# V32F20x_CM0 register map
File version: 1.0.1
CPU: CM0 r0p0, little endian, no MPU, no FPU, 2 interrupt priority bits
Registers are 32-bit, read-write, reset 0x0 unless marked. A register's access mark holds for its fields unless they carry their own. Offsets are from the block's base; [hi:lo] are bit positions; {n}, {i} and the like mark numbered series.

## BPWMMUX1 — BPWMMUX1 Peripheral Interface
Base 0x410501F0
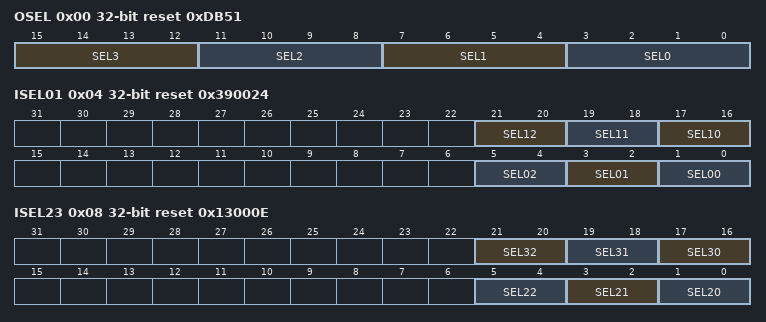
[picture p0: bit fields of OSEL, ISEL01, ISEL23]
0x00 OSEL reset 0xDB51 — BPWM output select register.
  [15:12] SEL3 — External output pin selected register for PWM3
  [11:8] SEL2 — External output pin selected register for PWM2
  [7:4] SEL1 — External output pin selected register for PWM1
  [3:0] SEL0 — External output pin selected register for PWM0.
0x04 ISEL01 reset 0x390024 — BPWM0 BPWM1 input select register.
  [21:20] SEL12 — The external input control of PWM1 channel 2 IN2
  [19:18] SEL11 — The external input control of PWM1 channel 1 IN1
  [17:16] SEL10 — The external output control of PWM1 channel 0 IN0
  [5:4] SEL02 — The external input control of PWM0 channel 2 IN2
  [3:2] SEL01 — The external input control of PWM0 channel 1 IN1
  [1:0] SEL00 — The external input control of PWM0 channel 0 IN0
0x08 ISEL23 reset 0x13000E — BPWM2 BPWM3 input select register.
  [21:20] SEL32 — The external input control of PWM3 channel 2 IN2
  [19:18] SEL31 — The external input control of PWM3 channel 1 IN1
  [17:16] SEL30 — The external input control of PWM3 channle 0 IN0
  [5:4] SEL22 — The external input control of PWM2 channel 2 IN2
  [3:2] SEL21 — The external input control of PWM2 channel 1 IN1
  [1:0] SEL20 — The external input control of PWM2 channel 0 IN0

## BDMA — BDMA Peripheral Interface
Base 0x41080800
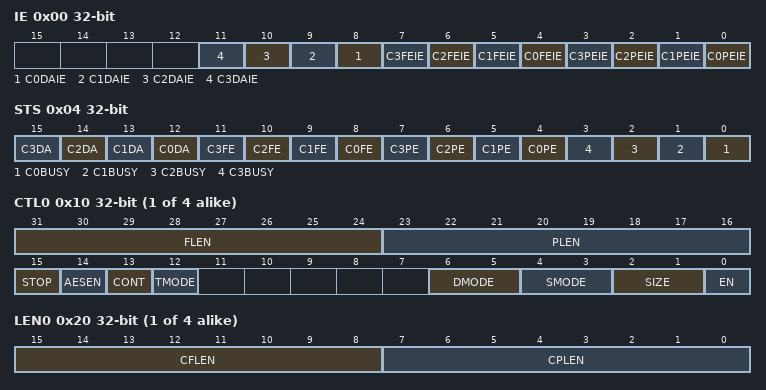
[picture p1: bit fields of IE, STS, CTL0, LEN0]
0x00 IE — BDMA interrupt enable register.
  [n+8] C{n}DAIE (n=0..3) — Channel {n} data abort interrupt enable
  [n+4] C{n}FEIE (n=0..3) — Channel {n} frame end interrupt enable
  [n] C{n}PEIE (n=0..3) — Channel {n} package end interrupt enable
0x04 STS — BDMA status register.
  [n+12] C{n}DA (n=0..3) — Channel {n} data about interrupt flag.
  [n+8] C{n}FE (n=0..3) — Channel {n} frame end interrupt flag.
  [n+4] C{n}PE (n=0..3) — Channel {n} package end interrupt flag.
  [n] C{n}BUSY (n=0..3) — DMA channel {n} busy
{0x10+0x20*i} CTL{i} (i=0..3) — BDMA channel x control register.
  [31:24] FLEN — Frame length
  [23:16] PLEN — Package length
  [15] STOP — Force stop DMA transfer
  [14] AESEN — Enable AES encrypt/decrypt function of DMA channel
  [13] CONT — Continuous mode
  [12] TMODE — Transfer mode selection
  [6:5] DMODE — Destination address mode
  [4:3] SMODE — Source address mode
  [2:1] SIZE — Transfer size mode
  [0] EN — DMA channel enable
{0x14+0x20*i} SEL{i} (i=0..3) — BDMA channel x request select.
  [5:0] DMASEL — DMA request source selection
{0x18+0x20*i} SRC{i} (i=0..3) — BDMA channel x source address register.
  [31:0] SRC — Source address register.
{0x1C+0x20*i} DST{i} (i=0..3) — BDMA channel x destination address register.
  [31:0] DST — Source address register.
{0x20+0x20*i} LEN{i} ro (i=0..3) — BDMA channel x transfer length register.
  [15:8] CFLEN — Current frame transferred length.
  [7:0] CPLEN — Current package transferred length.
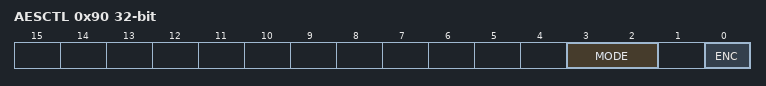
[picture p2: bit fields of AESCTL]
0x90 AESCTL — BDMA AES control register.
  [3:2] MODE — AES mode selection register.
  [0] ENC — AES encode/decode selection register.
{0xA0+4i} AESKEY{i} (i=0..7) — BDMA AES key x register.
  [31:0] KEYx — AES KEY register.

## WDT2 — WDT2 Peripheral Interface
Base 0x41090000
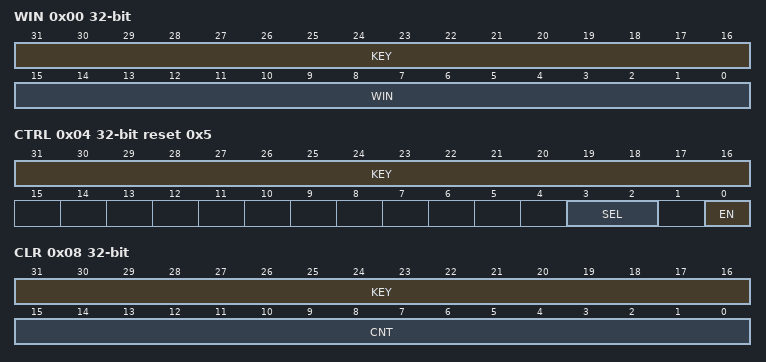
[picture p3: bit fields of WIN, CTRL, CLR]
0x00 WIN — Watchdog window value register.
  [31:16] KEY — Writes to the WDT_WIN register must be accompanied by a write of the value 0xAA55 to this field
  [15:0] WIN — Watch dog window value configuration.
0x04 CTRL reset 0x5 — Watchdog control register.
  [31:16] KEY — Writes to the WDT_CTRL register must be accompanied by a write of the value 0xAA55 to this field
  [3:2] SEL — This register is used to control the WDT counting period
  [0] EN — WDT enable configuration:
0x08 CLR — Watchdog clear register.
  [31:16] KEY — Writes to the WDT_CLR register must be accompanied by a write of the value 0x55AA to this field
  [15:0] CNT — Watchdog counter value.
0x0C STS — Watchdog status register.
  [0] STS
